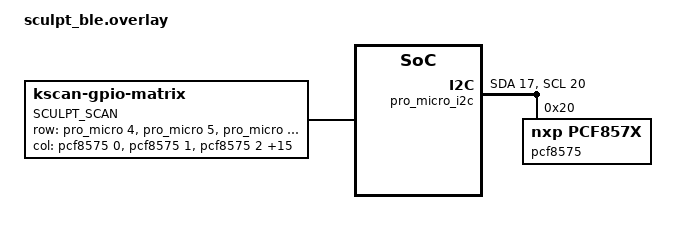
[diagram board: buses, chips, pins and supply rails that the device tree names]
#include <dt-bindings/gpio/gpio.h>

/*
 * Shield: Sculpt BLE
 * MCU: nice!nano (pro_micro compatible)
 *
 * Matrix:
 *   8 rows on MCU pins:
 *     ROW1..ROW8 -> D4, D5, D6, D7, D8, D9, D10, D16
 *
 *   18 columns:
 *     COL_A..COL_P -> PCF8575 P0_0..P1_7 (I2C @ 0x20)
 *     COL_Q, COL_R -> D14, D15 on the nice!nano
 */
 
 / {
    chosen {
        zmk,kscan = &sculpt_scan;
    };
};

/* I2C bus for the PCF8575 */
&pro_micro_i2c {
    status = "okay";
    sda-pin = <17>;
    scl-pin = <20>;

    pcf8575: gpio-expander@20 {
        compatible = "nxp,pcf857x";
        reg = <0x20>;
        status = "okay";
        gpio-controller;
        #gpio-cells = <2>;
        ngpios = <16>;
    };
};

&pro_micro {
    sculpt_scan: kscan {
        compatible = "zmk,kscan-gpio-matrix";
        label = "SCULPT_SCAN";

        /* Your real matrix dimensions */
        rows = <8>;
        cols = <18>;

        /* Correct for Sculpt: rows are driven low, cols are read */
        diode-direction = "col2row";

        /* ---------- ROWS (8) — ALL FROM MCU ---------- */

        /* YES: Each row is exactly the FPC→D4..D16 list you confirmed */
        row-gpios = <
            &pro_micro 4  GPIO_ACTIVE_HIGH    /* ROW0 = FPC29 → D4  */
            &pro_micro 5  GPIO_ACTIVE_HIGH    /* ROW1 = FPC28 → D5  */
            &pro_micro 6  GPIO_ACTIVE_HIGH    /* ROW2 = FPC27 → D6  */
            &pro_micro 7  GPIO_ACTIVE_HIGH    /* ROW3 = FPC26 → D7  */
            &pro_micro 8  GPIO_ACTIVE_HIGH    /* ROW4 = FPC25 → D8  */
            &pro_micro 9  GPIO_ACTIVE_HIGH    /* ROW5 = FPC24 → D9  */
            &pro_micro 10 GPIO_ACTIVE_HIGH    /* ROW6 = FPC23 → D10 */
            &pro_micro 16 GPIO_ACTIVE_HIGH    /* ROW7 = FPC22 → D16 */
        >;

        /* ---------- COLS (18) — PCF0-15 + MCU D14/D15 ---------- */

        col-gpios = <
            /* PCF8575 pins P00–P17 become columns 0–15 */
            &pcf8575 0  GPIO_ACTIVE_HIGH    /* COL0  = P00 */
            &pcf8575 1  GPIO_ACTIVE_HIGH    /* COL1  = P01 */
            &pcf8575 2  GPIO_ACTIVE_HIGH    /* COL2  = P02 */
            &pcf8575 3  GPIO_ACTIVE_HIGH    /* COL3  = P03 */
            &pcf8575 4  GPIO_ACTIVE_HIGH    /* COL4  = P04 */
            &pcf8575 5  GPIO_ACTIVE_HIGH    /* COL5  = P05 */
            &pcf8575 6  GPIO_ACTIVE_HIGH    /* COL6  = P06 */
            &pcf8575 7  GPIO_ACTIVE_HIGH    /* COL7  = P07 */

            &pcf8575 8  GPIO_ACTIVE_HIGH    /* COL8  = P10 */
            &pcf8575 9  GPIO_ACTIVE_HIGH    /* COL9  = P11 */
            &pcf8575 10 GPIO_ACTIVE_HIGH    /* COL10 = P12 */
            &pcf8575 11 GPIO_ACTIVE_HIGH    /* COL11 = P13 */
            &pcf8575 12 GPIO_ACTIVE_HIGH    /* COL12 = P14 */
            &pcf8575 13 GPIO_ACTIVE_HIGH    /* COL13 = P15 */
            &pcf8575 14 GPIO_ACTIVE_HIGH    /* COL14 = P16 */
            &pcf8575 15 GPIO_ACTIVE_HIGH    /* COL15 = P17 */

            /* MCU columns */
            &pro_micro 14 GPIO_ACTIVE_HIGH   /* COL16 = D14 (COL_Q) */
            &pro_micro 15 GPIO_ACTIVE_HIGH   /* COL17 = D15 (COL_R) */
        >;
    };
};
